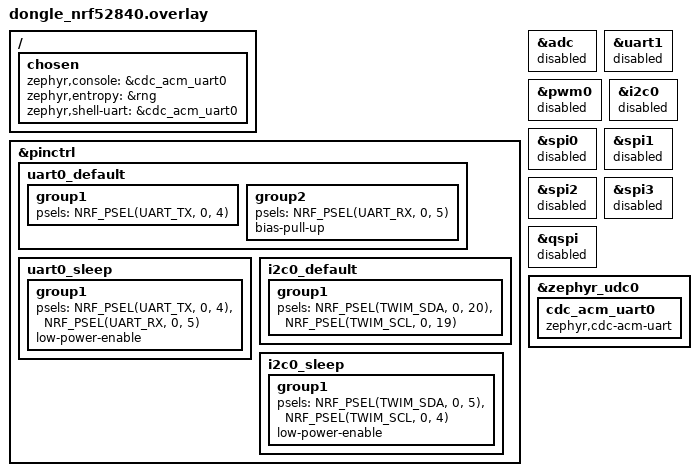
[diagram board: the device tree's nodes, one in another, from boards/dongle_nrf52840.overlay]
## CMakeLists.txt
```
#
# Copyright (c) 2020 Nordic Semiconductor ASA
#
# SPDX-License-Identifier: LicenseRef-Nordic-5-Clause
#
cmake_minimum_required(VERSION 3.20.0)

find_package(Zephyr REQUIRED HINTS $ENV{ZEPHYR_BASE})

project(thread_coap_client_dongle_camera)

# NORDIC SDK APP START
target_sources(app PRIVATE src/thread_dongle_client.c
                  src/coap_client_utils.c)

target_include_directories(app PUBLIC ../thread_dongle_server/interface)
# NORDIC SDK APP END
```

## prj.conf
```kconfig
#
# Copyright (c) 2020 Nordic Semiconductor
#
# SPDX-License-Identifier: LicenseRef-Nordic-5-Clause
#

# nRF board library
CONFIG_DK_LIBRARY=y

# Enable CoAP utils and CoAP protocol
CONFIG_COAP_UTILS=y

# Generic networking options
CONFIG_NETWORKING=y

# L2 OpenThread enabling
CONFIG_NET_L2_OPENTHREAD=y

# Network shell
CONFIG_SHELL=y
CONFIG_OPENTHREAD_SHELL=y
CONFIG_SHELL_ARGC_MAX=26
CONFIG_SHELL_CMD_BUFF_SIZE=416

# Network sockets
CONFIG_NET_SOCKETS=y
CONFIG_NET_SOCKETS_POSIX_NAMES=y
CONFIG_NET_SOCKETS_POLL_MAX=4

# Same network Master Key for client and server
CONFIG_OPENTHREAD_NETWORKKEY="00:11:22:33:44:55:66:77:88:99:aa:bb:cc:dd:ee:ff"

CONFIG_MBEDTLS_SHA1_C=n
CONFIG_FPU=y

# UART conf
CONFIG_SERIAL=y
CONFIG_UART_ASYNC_API=y
CONFIG_UART_0_ASYNC=y
CONFIG_UART_0_INTERRUPT_DRIVEN=n
CONFIG_NRFX_UARTE0=y
```

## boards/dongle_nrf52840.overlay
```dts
/* Copyright (c) 2020 Nordic Semiconductor ASA
 *
 * SPDX-License-Identifier: LicenseRef-Nordic-5-Clause
 */

/ {
    /*
    * In some default configurations within the nRF Connect SDK,
    * e.g. on nRF52840, the chosen zephyr,entropy node is &cryptocell.
    * This devicetree overlay ensures that default is overridden wherever it
    * is set, as this application uses the RNG node for entropy exclusively.
    */
    chosen {
        zephyr,console = &cdc_acm_uart0;
        zephyr,entropy = &rng;
        zephyr,shell-uart = &cdc_acm_uart0;
    };
};
&pinctrl {
    uart0_default: uart0_default {
        group1 {
            psels = <NRF_PSEL(UART_TX, 0, 4)>;
        };
        group2 {
            psels = <NRF_PSEL(UART_RX, 0, 5)>;
            bias-pull-up;
        };          
    };

    uart0_sleep: uart0_sleep {
        group1 {
            psels = <NRF_PSEL(UART_TX, 0, 4)>,
                <NRF_PSEL(UART_RX, 0, 5)>;
            low-power-enable;
        };
    };

    i2c0_default: i2c0_default {
        group1 {
            psels = <NRF_PSEL(TWIM_SDA, 0, 20)>,
                <NRF_PSEL(TWIM_SCL, 0, 19)>;
        };
    };

    i2c0_sleep: i2c0_sleep {
        group1 {
            psels = <NRF_PSEL(TWIM_SDA, 0, 5)>,
                <NRF_PSEL(TWIM_SCL, 0, 4)>;
            low-power-enable;
        };
    };
};

&adc {
    status = "disabled";
};
&uart1 {
    status = "disabled";
};
&pwm0 {
    status = "disabled";
};
&i2c0 {
    status = "disabled";
};
&spi0 {
    status = "disabled";
};
&spi1 {
    status = "disabled";
};
&spi2 {
    status = "disabled";
};
&spi3 {
    status = "disabled";
};
&qspi {
    status = "disabled";
};

&zephyr_udc0 {
    cdc_acm_uart0: cdc_acm_uart0 {
        compatible = "zephyr,cdc-acm-uart";
    };
};
```

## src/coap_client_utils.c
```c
/*
 * Copyright (c) 2020 Nordic Semiconductor ASA
 *
 * SPDX-License-Identifier: LicenseRef-Nordic-5-Clause
 */

#include <zephyr/kernel.h>
#include <thread_dongle_interface.h>
#include <dk_buttons_and_leds.h>
#include <net/coap_utils.h>
#include <zephyr/logging/log.h>
#include <zephyr/net/openthread.h>
#include <zephyr/net/socket.h>
#include <openthread/thread.h>

#include "coap_client_utils.h"

static bool is_connected;

static struct k_work multicast_commands_work;
static struct k_work ressources_status_work;
static struct k_work send_alarm_work;
static struct k_work wifi_status_work;
static struct k_work presence_status_work;
static struct k_work electrical_status_work;
static struct k_work on_connect_work;
static struct k_work on_disconnect_work;

/* Options supported by the server */
static const char *const commands_option[] = { COMMANDS_URI_PATH, NULL };
static const char *const ressources_status_option[] = { RESSOURCES_URI_PATH, NULL };
static const char *const wifi_status_option[] = { WIFI_URI_PATH, NULL };
static const char *const presence_status_option[] = { PRESENCE_URI_PATH, NULL };
static const char *const electrical_status_option[] = { ELECTRIC_URI_PATH, NULL };

volatile uint8_t msg_buf[MSG_BUFF_SIZE] = {0};
uint16_t msg_len = 0;

/* Thread multicast mesh local address */
static struct sockaddr_in6 multicast_local_addr = {
     .sin6_family = AF_INET6,
     .sin6_port = htons(COAP_PORT),
     .sin6_addr.s6_addr = { 0xff, 0x03, 0x00, 0x00, 0x00, 0x00, 0x00, 0x00,
                      0x00, 0x00, 0x00, 0x00, 0x00, 0x00, 0x00, 0x01 },
     .sin6_scope_id = 0U
};

// Variable for storing orchestrator server ressources */
struct server_ressources {
    bool wifi_status;
    bool presence_status;
    bool electrical_status;
};

static struct server_ressources srv_ressources = {
    .wifi_status = NULL,
    .presence_status = NULL,
    .electrical_status = NULL,
};

static int on_commands_msg_reply(const struct coap_packet *response,
                     struct coap_reply *reply,
                     const struct sockaddr *from)
{
     ARG_UNUSED(reply);
     ARG_UNUSED(from);   

     const uint8_t *payload;
     uint16_t payload_size = 0u; 
     char *cmd_ok = "CMD:OK";

     dk_set_led_off(RESSOURCES_STATUS_MSG_LED);

     payload = coap_packet_get_payload(response, &payload_size);

     // Check if CMD:OK in payload
     if (strstr(payload, cmd_ok) != NULL) {
          printk("THREAD [DEBBUG]: commands msg reply: CMD_ACK\r\n"); 
          dk_set_led_off(COMMANDS_MSG_LED);     
     }
exit:
     return 0;
}


static void send_commands_to_server_message(struct k_work *item)
{
     ARG_UNUSED(item);

     printk("THREAD [DEBBUG]: Sending command to server \r\n");

     int ret_coap_req = coap_send_request(
          COAP_METHOD_PUT,(const struct sockaddr *)&multicast_local_addr,
          commands_option, &msg_buf, msg_len, on_commands_msg_reply);
     
     dk_set_led_on(COMMANDS_MSG_LED);

     // Clear buffer
     msg_len = 0;
     for( int i =0; i < MSG_BUFF_SIZE; i++ ){
          msg_buf[i] = NULL;
     }     
}

static int on_ressource_status_reply(const struct coap_packet *response,
                     struct coap_reply *reply,
                     const struct sockaddr *from)
{
     const uint8_t *payload;
     uint16_t payload_size = 0u;

     ARG_UNUSED(reply);
     ARG_UNUSED(from);

     printk("THREAD [DEBBUG]: Ressource status reply received from server \r\n");     

     dk_set_led_off(RESSOURCES_STATUS_MSG_LED);

     payload = coap_packet_get_payload(response, &payload_size); 

     // Check if wifi in payload
     char* wifi_in_payload = strchr(payload, 'w');
     if(*wifi_in_payload != NULL){
          const char wifi_status_char = (char)wifi_in_payload[5];
          srv_ressources.wifi_status = wifi_status_char == '1' ? true : false;        
     }
     
     // Check if presence in payload
     char* presence_in_payload = strchr(payload, 'p');
     if(*presence_in_payload != NULL){
          const char presence_status_char = (char)presence_in_payload[4];
          srv_ressources.presence_status = presence_status_char == '1' ? true : false;              
     }

     // Check if electrical in payload
     char* electrical_in_payload = strchr(payload, 'e');
     if(*electrical_in_payload != NULL){
          const char electrical_status_char = (char)electrical_in_payload[4];
          srv_ressources.electrical_status = electrical_status_char == '1' ? true : false;              
     }

     print_orchestrator_server_ressources();
exit:
     return 0;
}

static void send_ressources_status_request(struct k_work *item)
{
     ARG_UNUSED(item);

     printk("THREAD [DEBBUG]: Sending ressources status request to server \r\n");

     coap_send_request(COAP_METHOD_GET,
                 (const struct sockaddr *)&multicast_local_addr,
                 ressources_status_option, NULL, 0u, on_ressource_status_reply);
     dk_set_led_on(RESSOURCES_STATUS_MSG_LED);
}

static void send_alarm(struct k_work *item)
{
     ARG_UNUSED(item);

     printk("THREAD [DEBBUG]: Sending alarm to server \r\n");

     static uint8_t msg_buf[] = ALARM;
     uint16_t msg_len = sizeof(msg_buf);

     int ret_coap_req = coap_send_request(
          COAP_METHOD_PUT,(const struct sockaddr *)&multicast_local_addr,
          commands_option, &msg_buf, msg_len, on_commands_msg_reply);
     
     dk_set_led_on(COMMANDS_MSG_LED);
}


static void send_wifi_status_request(struct k_work *item)
{
     ARG_UNUSED(item);

     printk("THREAD [DEBBUG]: Sending wifi status request to server \r\n");

     coap_send_request(COAP_METHOD_GET,
                 (const struct sockaddr *)&multicast_local_addr,
                 wifi_status_option, NULL, 0u, on_ressource_status_reply);
     dk_set_led_on(RESSOURCES_STATUS_MSG_LED);
}

static void send_presence_status_request(struct k_work *item)
{
     ARG_UNUSED(item);

     printk("THREAD [DEBBUG]: Sending presence status request to server \r\n");

     coap_send_request(COAP_METHOD_GET,
                 (const struct sockaddr *)&multicast_local_addr,
                 presence_status_option, NULL, 0u, on_ressource_status_reply);
     dk_set_led_on(RESSOURCES_STATUS_MSG_LED);
}

static void send_electrical_status_request(struct k_work *item)
{
     ARG_UNUSED(item);

     printk("THREAD [DEBBUG]: Sending electrical status request to server \r\n");

     coap_send_request(COAP_METHOD_GET,
                 (const struct sockaddr *)&multicast_local_addr,
                 electrical_status_option, NULL, 0u, on_ressource_status_reply);
     dk_set_led_on(RESSOURCES_STATUS_MSG_LED);
}

static void on_thread_state_changed(otChangedFlags flags, struct openthread_context *ot_context,
                        void *user_data)
{
     if (flags & OT_CHANGED_THREAD_ROLE) {
          switch (otThreadGetDeviceRole(ot_context->instance)) {
          case OT_DEVICE_ROLE_CHILD:
          case OT_DEVICE_ROLE_ROUTER:
          case OT_DEVICE_ROLE_LEADER:
               k_work_submit(&on_connect_work);
               is_connected = true;
               break;

          case OT_DEVICE_ROLE_DISABLED:
          case OT_DEVICE_ROLE_DETACHED:
          default:
               k_work_submit(&on_disconnect_work);
               is_connected = false;
               break;
          }
     }
}

static struct openthread_state_changed_cb ot_state_chaged_cb = {
     .state_changed_cb = on_thread_state_changed
};

static void submit_work_if_connected(struct k_work *work)
{         
     if (is_connected) {
          k_work_submit(work);
     } else {
          printk("THREAD [ERROR]: Connection is broken \r\n");
     }
}

void coap_client_utils_init(ot_connection_cb_t on_connect, ot_disconnection_cb_t on_disconnect)
{

     coap_init(AF_INET6, NULL);

     k_work_init(&on_connect_work, on_connect);
     k_work_init(&on_disconnect_work, on_disconnect);
     k_work_init(&multicast_commands_work, send_commands_to_server_message);
     k_work_init(&ressources_status_work, send_ressources_status_request);
     k_work_init(&send_alarm_work, send_alarm);
     k_work_init(&wifi_status_work, send_wifi_status_request);
     k_work_init(&presence_status_work, send_presence_status_request);
     k_work_init(&electrical_status_work, send_electrical_status_request);

     openthread_state_changed_cb_register(openthread_get_default_context(), &ot_state_chaged_cb);
     openthread_start(openthread_get_default_context());
}

void coap_client_send_commands_to_server_message(uint8_t* msg, uint16_t msg_length)
{    
     msg_len = msg_length;
     // copy message to send to buffer
     for( int i =0; i < msg_length; i++ ){
          msg_buf[i] = msg[i];
     }     
     submit_work_if_connected(&multicast_commands_work);
}

void coap_client_send_ressources_status_request(void)
{
     submit_work_if_connected(&ressources_status_work);
}

void coap_client_send_alarm(void)
{
     submit_work_if_connected(&send_alarm_work);
}

void coap_client_send_wifi_status_request(void)
{
     submit_work_if_connected(&wifi_status_work);
}

void coap_client_send_presence_status_request(void)
{
     submit_work_if_connected(&presence_status_work);
}

void coap_client_send_electrical_status_request(void)
{
     submit_work_if_connected(&electrical_status_work);
}

void print_orchestrator_server_ressources(void){
     printk("ORCHESTRATOR [DEBBUG]: Server ressources   ");
     printk("wifi: %s   ", srv_ressources.wifi_status ? "true" : "false");
     printk("presence: %s\n\r", srv_ressources.presence_status ? "true" : "false");   
     printk("electrical: %s\n\r", srv_ressources.electrical_status ? "true" : "false");     
}

bool get_server_wifi_status(void){
     return srv_ressources.wifi_status;
}

bool get_server_presence_status(void){
     return srv_ressources.presence_status;
}

bool get_server_electrical_status(void){
     return srv_ressources.electrical_status;
}
```

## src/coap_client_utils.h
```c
/**
 * @file
 * @defgroup coap_client_utils API for coap_client_* samples
 * @{
 */

/*
 * Copyright (c) 2020 Nordic Semiconductor ASA
 *
 * SPDX-License-Identifier: LicenseRef-Nordic-5-Clause
 */

#ifndef __COAP_CLIENT_UTILS_H__
#define __COAP_CLIENT_UTILS_H__

/** @brief Type indicates function called when OpenThread connection
 *         is established.
 *
 * @param[in] item pointer to work item.
 */
typedef void (*ot_connection_cb_t)(struct k_work *item);

/** @brief Type indicates function called when OpenThread connection is ended.
 *
 * @param[in] item pointer to work item.
 */
typedef void (*ot_disconnection_cb_t)(struct k_work *item);

/** @brief Initialize CoAP client utilities.
 */
void coap_client_utils_init(ot_connection_cb_t on_connect,
                   ot_disconnection_cb_t on_disconnect);

/** @brief Send a action to the CoAP server node.
 *
 * @note The CoAP server should be paired before to have an affect.
 */
void coap_client_send_commands_to_server_message(uint8_t* msg, uint16_t msg_length);

/** @brief Request for the CoAP ressources status ressource.
 *
 */
void coap_client_send_ressources_status_request(void);

/** @brief Request for the CoAP wifi status ressource.
 *
 */
void coap_client_send_wifi_status_request(void);

/** @brief Request for post button alarm.
 *
 */
void coap_client_send_alarm(void);

/** @brief Request for the CoAP presence status ressource.
 *
 */
void coap_client_send_presence_status_request(void);

/** @brief Print the orchestrator server ressources status.
 *
 */
void print_orchestrator_server_ressources(void);

/** @brief Returns the orchestrator wifi status.
 *
 */
bool get_server_wifi_status(void);

/** @brief Returns the orchestrator presence status.
 *
 */
bool get_server_presence_status(void);




#endif

/**
 * @}
 */
```

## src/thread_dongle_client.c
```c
/*
 * Copyright (c) 2020 Nordic Semiconductor ASA
 * Copyright (c) 2016-2023 Makerdiary
 *
 * SPDX-License-Identifier: LicenseRef-Nordic-5-Clause
 */

#include <zephyr/kernel.h>
#include <dk_buttons_and_leds.h>
#include <zephyr/logging/log.h>
#include <zephyr/device.h>
#include <zephyr/pm/device.h>
#include <zephyr/sys/printk.h>
#include <zephyr/drivers/uart.h>
#include <thread_dongle_interface.h>

#include "coap_client_utils.h"

// Server polling period
#define SERVER_POLLING_PERIOD_MS 10000

// UART variables
#define UART_RECEIVE_TIMEOUT 500000
#define START_CHAR '~'
#define END_CHAR '#'

const struct device *uart= DEVICE_DT_GET(DT_NODELABEL(uart0));
static uint8_t rx_buf[MSG_BUFF_SIZE] = {0};
static uint8_t rx_msg_buf[MSG_MAX_SIZE] = {0};
static uint8_t rx_offset=0;

/*Send the server ressources status via uart*/
static void uart_send_server_ressources_status(){

    bool wifi_status = get_server_wifi_status();
    bool presence_status = get_server_presence_status();
    bool electrical_status = get_server_electrical_status();

    printk("SERVER [DEBBUG]: current ressources status  wifi:%d   presence:%d   electrical:%d\r\n", wifi_status, presence_status, electrical_status);

    // msg buffer
    static uint8_t tx_buf[] =   "~wifi:0prs:0ele:0#";

    // Add wifi status
    if(wifi_status){tx_buf[6] = '1';}
    else{tx_buf[6] = '0';}

    // Add presence status
    if(presence_status){tx_buf[11] = '1';}
    else{tx_buf[11] = '0';}

    // Add electrical status
    if(electrical_status){tx_buf[16] = '1';}
    else{tx_buf[16] = '0';}

    int ret = uart_tx(uart, tx_buf, sizeof(tx_buf), SYS_FOREVER_MS);
    printk("UART [DEBBUG]: Sending ressources status via UART: %s\r\n", tx_buf);
    if (ret) {
        printk("UART [ERROR]: Impossible to send message over UART\r\n");
        return 1;
    }
}
/* Process received char from UART */
static void process_received_char(char received_char)
{
	if(received_char == START_CHAR){
		// Empty msg buffer
		for( int i =0; i < MSG_MAX_SIZE; i++ ){
			rx_msg_buf[i] = NULL;
        }
		rx_offset = 0;
		return;
	}
	if(received_char == END_CHAR){
		printk("UART [DEBBUG]: Received message: ");
		for( int i =0; i < rx_offset; i++ ){
			printk("%c", rx_msg_buf[i]);
        }
		printk("\r\n");
        printk("THREAD [DEBBUG]: Transfer received message via thread\r\n");
         
        coap_client_send_commands_to_server_message(&rx_msg_buf, rx_offset);        
		return;
	}
	else{
		rx_msg_buf[rx_offset]=received_char;
		rx_offset ++;
		return;
	}

} 

/*Callback for uart messages reception*/
static void on_uart_message(const struct device *uart_dev, struct uart_event *evt, void *user_data)
{
    //printk("UART event\r\n");
	switch (evt->type) {				
	case UART_RX_RDY:
        for( int i =0; i < evt->data.rx.len; i++ ){
			process_received_char(evt->data.rx.buf[evt->data.rx.offset + i]);
        }	
		break;			
	case UART_RX_DISABLED:
		uart_rx_enable(uart_dev, rx_buf, sizeof(rx_buf), UART_RECEIVE_TIMEOUT);
		break;
	default:
		break;
	}
}

static void on_ot_connect(struct k_work *item)
{
    ARG_UNUSED(item);
    dk_set_led_on(OT_CONNECTION_LED);
}

static void on_ot_disconnect(struct k_work *item)
{
    ARG_UNUSED(item);
    dk_set_led_off(OT_CONNECTION_LED);
}

static void on_button_changed(uint32_t button_state, uint32_t has_changed)
{
    uint32_t buttons = button_state & has_changed;
    if (buttons & DK_BTN1_MSK) {
        coap_client_send_alarm();
    }
}

int main(void)
{
    int ret;

    ret = dk_buttons_init(on_button_changed);
    if (ret) {
        printk("BUTTONS [ERROR]: Cannot init buttons (error: %d)", ret);
        return 0;
    }

    ret = dk_leds_init();
    if (ret) {
        printk("LEDS [ERROR]: Cannot init leds, (error: %d)", ret);
        return 0;
    }

    if (!device_is_ready(uart)){
		printk("UART [ERROR]: UART device not ready\r\n");
		return 1 ;
	}

    // Init thread/coap
    coap_client_utils_init(on_ot_connect, on_ot_disconnect);
    
    // Structure to configure uart communication
    const struct uart_config uart_cfg = {
		.baudrate = 115200,
		.parity = UART_CFG_PARITY_NONE,
		.stop_bits = UART_CFG_STOP_BITS_1,
		.data_bits = UART_CFG_DATA_BITS_8,
		.flow_ctrl = UART_CFG_FLOW_CTRL_NONE
	};

    // Configure uart0 device
    ret = uart_configure(uart, &uart_cfg);
	if (ret == -ENOSYS) {
		return -ENOSYS;
	}

    // Register uart callback function    
    ret = uart_callback_set(uart, on_uart_message, NULL);
    if (ret) {
        printk("UART [ERROR]: Imposible to registre callback ret=%d\r\n", ret);	
        return 1;
    } 

    // Start uart receiving reception in buffer
    uart_rx_enable(uart, rx_buf, sizeof(rx_buf), UART_RECEIVE_TIMEOUT);
    
    // loop forever waiting for uart messages
    while (1) {                
        coap_client_send_ressources_status_request();
        k_msleep(SERVER_POLLING_PERIOD_MS*0.2); 
        uart_send_server_ressources_status();
        k_msleep(SERVER_POLLING_PERIOD_MS*0.8);     
	}
    return 0;
}
```
